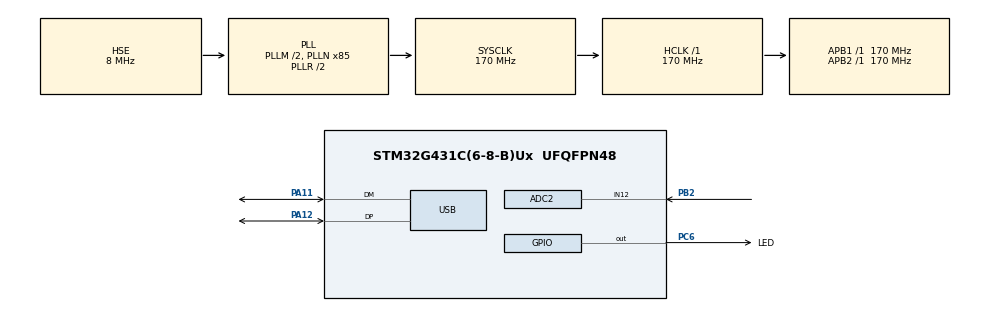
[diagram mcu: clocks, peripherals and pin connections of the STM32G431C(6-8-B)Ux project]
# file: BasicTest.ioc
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ADC2.Channel-0\#ChannelRegularConversion=ADC_CHANNEL_12
ADC2.ContinuousConvMode=ENABLE
ADC2.DMAContinuousRequests=ENABLE
ADC2.NbrOfConversionFlag=1
ADC2.OffsetNumber-0\#ChannelRegularConversion=ADC_OFFSET_NONE
ADC2.Rank-0\#ChannelRegularConversion=1
ADC2.SamplingTime-0\#ChannelRegularConversion=ADC_SAMPLETIME_640CYCLES_5
Dma.ADC2.0.Direction=DMA_PERIPH_TO_MEMORY
Dma.ADC2.0.EventEnable=DISABLE
Dma.ADC2.0.Instance=DMA1_Channel1
Dma.ADC2.0.MemDataAlignment=DMA_MDATAALIGN_HALFWORD
Dma.ADC2.0.MemInc=DMA_MINC_ENABLE
Dma.ADC2.0.Mode=DMA_CIRCULAR
Dma.ADC2.0.PeriphDataAlignment=DMA_PDATAALIGN_HALFWORD
Dma.ADC2.0.PeriphInc=DMA_PINC_DISABLE
Dma.ADC2.0.Polarity=HAL_DMAMUX_REQ_GEN_RISING
Dma.ADC2.0.Priority=DMA_PRIORITY_LOW
Dma.ADC2.0.RequestNumber=1
Dma.ADC2.0.SignalID=NONE
Dma.ADC2.0.SyncEnable=DISABLE
Dma.ADC2.0.SyncPolarity=HAL_DMAMUX_SYNC_NO_EVENT
Dma.ADC2.0.SyncRequestNumber=1
Dma.ADC2.0.SyncSignalID=NONE
Dma.Request0=ADC2
FREERTOS.Tasks01=defaultTask,0,128,StartDefaultTask,Default,NULL,Dynamic,NULL,NULL
Mcu.Family=STM32G4
Mcu.Name=STM32G431C(6-8-B)Ux
Mcu.Package=UFQFPN48
NVIC.DMA1_Channel1_IRQn=true\:5\:0\:false\:false\:true\:true\:false\:true\:true
NVIC.PriorityGroup=NVIC_PRIORITYGROUP_4
NVIC.TIM1_TRG_COM_TIM17_IRQn=true\:15\:0\:false\:false\:true\:false\:false\:true\:true
NVIC.TimeBase=TIM1_TRG_COM_TIM17_IRQn
NVIC.TimeBaseIP=TIM17
NVIC.USB_LP_IRQn=true\:5\:0\:false\:false\:true\:true\:false\:true\:true
PA11.Mode=Device
PA11.Signal=USB_DM
PA12.Mode=Device
PA12.Signal=USB_DP
PA13.Mode=Serial_Wire
PA13.Signal=SYS_JTMS-SWDIO
PA14.Mode=Serial_Wire
PA14.Signal=SYS_JTCK-SWCLK
PB2.Mode=IN12-Single-Ended
PB2.Signal=ADC2_IN12
PC6.GPIO_Label=LED
PC6.GPIO_PuPd=GPIO_PULLDOWN
PC6.GPIO_Speed=GPIO_SPEED_FREQ_LOW
PC6.PinState=GPIO_PIN_RESET
PC6.Signal=GPIO_Output
PF0-OSC_IN.Mode=HSE-External-Oscillator
PF0-OSC_IN.Signal=RCC_OSC_IN
PF1-OSC_OUT.Mode=HSE-External-Oscillator
PF1-OSC_OUT.Signal=RCC_OSC_OUT
ProjectManager.HeapSize=0x100
ProjectManager.StackSize=0xA00
ProjectManager.TargetToolchain=MDK-ARM V5.32
RCC.ADC12Freq_Value=170000000
RCC.AHBFreq_Value=170000000
RCC.APB1Freq_Value=170000000
RCC.APB1TimFreq_Value=170000000
RCC.APB2Freq_Value=170000000
RCC.APB2TimFreq_Value=170000000
RCC.CK48CLockSelection=RCC_USBCLKSOURCE_HSI48
RCC.CortexFreq_Value=170000000
RCC.EXTERNAL_CLOCK_VALUE=12288000
RCC.HCLKFreq_Value=170000000
RCC.HSE_VALUE=8000000
RCC.HSI48_VALUE=48000000
RCC.HSI_VALUE=16000000
RCC.LSE_VALUE=32768
RCC.PLLM=RCC_PLLM_DIV2
RCC.PLLN=85
RCC.PLLSourceVirtual=RCC_PLLSOURCE_HSE
RCC.SYSCLKFreq_VALUE=170000000
RCC.SYSCLKSource=RCC_SYSCLKSOURCE_PLLCLK
RCC.USBFreq_Value=48000000
RCC.VCOOutputFreq_Value=340000000
TIM7.Prescaler=169
USB_DEVICE.CLASS_NAME_FS=CDC
USB_DEVICE.VirtualMode=Cdc
USB_DEVICE.VirtualModeFS=Cdc_FS
VP_FREERTOS_VS_CMSIS_V1.Mode=CMSIS_V1
VP_SYS_VS_DBSignals.Mode=DisableDeadBatterySignals
VP_SYS_VS_tim17.Mode=TIM17
VP_TIM7_VS_ClockSourceINT.Mode=Enable_Timer
VP_USB_DEVICE_VS_USB_DEVICE_CDC_FS.Mode=CDC_FS
board=custom

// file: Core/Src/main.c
/* USER CODE BEGIN Header */
/**
  ******************************************************************************
  * @file           : main.c
  * @brief          : Main program body
  ******************************************************************************
  * @attention
  *
  * Copyright (c) 2025 STMicroelectronics.
  * All rights reserved.
  *
  * This software is licensed under terms that can be found in the LICENSE file
  * in the root directory of this software component.
  * If no LICENSE file comes with this software, it is provided AS-IS.
  *
  ******************************************************************************
  */
/* USER CODE END Header */
#include "main.h"
#include "cmsis_os.h"
#include "adc.h"
#include "dma.h"
#include "tim.h"
#include "usb_device.h"
#include "gpio.h"

void SystemClock_Config(void);
void MX_FREERTOS_Init(void);

int main(void)
{

  /* MCU Configuration--------------------------------------------------------*/

  /* Reset of all peripherals, Initializes the Flash interface and the Systick. */
  HAL_Init();

  /* Configure the system clock */
  SystemClock_Config();

  /* Initialize all configured peripherals */
  MX_GPIO_Init();
  MX_DMA_Init();
  MX_USB_Device_Init();
  MX_ADC2_Init();
  MX_TIM7_Init();
  /* USER CODE BEGIN 2 */
  LL_TIM_SetCounter(TIM7, 0);
//	LL_TIM_EnableIT_UPDATE(TIM7);//start TIM7 IRQ
	LL_TIM_EnableCounter(TIM7);//Enable TIM7
  /* USER CODE END 2 */

  /* Call init function for freertos objects (in freertos.c) */
  MX_FREERTOS_Init();

  /* Start scheduler */
  osKernelStart();

  /* We should never get here as control is now taken by the scheduler */
  /* Infinite loop */
  while (1)
  {

  }
}

void SystemClock_Config(void)
{
  RCC_OscInitTypeDef RCC_OscInitStruct = {0};
  RCC_ClkInitTypeDef RCC_ClkInitStruct = {0};

  /** Configure the main internal regulator output voltage
  */
  HAL_PWREx_ControlVoltageScaling(PWR_REGULATOR_VOLTAGE_SCALE1_BOOST);

  /** Initializes the RCC Oscillators according to the specified parameters
  * in the RCC_OscInitTypeDef structure.
  */
  RCC_OscInitStruct.OscillatorType = RCC_OSCILLATORTYPE_HSI48|RCC_OSCILLATORTYPE_HSE;
  RCC_OscInitStruct.HSEState = RCC_HSE_ON;
  RCC_OscInitStruct.HSI48State = RCC_HSI48_ON;
  RCC_OscInitStruct.PLL.PLLState = RCC_PLL_ON;
  RCC_OscInitStruct.PLL.PLLSource = RCC_PLLSOURCE_HSE;
  RCC_OscInitStruct.PLL.PLLM = RCC_PLLM_DIV2;
  RCC_OscInitStruct.PLL.PLLN = 85;
  RCC_OscInitStruct.PLL.PLLP = RCC_PLLP_DIV2;
  RCC_OscInitStruct.PLL.PLLQ = RCC_PLLQ_DIV2;
  RCC_OscInitStruct.PLL.PLLR = RCC_PLLR_DIV2;
  if (HAL_RCC_OscConfig(&RCC_OscInitStruct) != HAL_OK)
  {
    Error_Handler();
  }

  /** Initializes the CPU, AHB and APB buses clocks
  */
  RCC_ClkInitStruct.ClockType = RCC_CLOCKTYPE_HCLK|RCC_CLOCKTYPE_SYSCLK
                              |RCC_CLOCKTYPE_PCLK1|RCC_CLOCKTYPE_PCLK2;
  RCC_ClkInitStruct.SYSCLKSource = RCC_SYSCLKSOURCE_PLLCLK;
  RCC_ClkInitStruct.AHBCLKDivider = RCC_SYSCLK_DIV1;
  RCC_ClkInitStruct.APB1CLKDivider = RCC_HCLK_DIV1;
  RCC_ClkInitStruct.APB2CLKDivider = RCC_HCLK_DIV1;

  if (HAL_RCC_ClockConfig(&RCC_ClkInitStruct, FLASH_LATENCY_4) != HAL_OK)
  {
    Error_Handler();
  }
}

void HAL_TIM_PeriodElapsedCallback(TIM_HandleTypeDef *htim)
{
  if (htim->Instance == TIM17) {
    HAL_IncTick();
  }
}

void Error_Handler(void)
{
  __disable_irq();
  while (1)
  {
  }
}

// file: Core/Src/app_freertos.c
/* USER CODE BEGIN Header */
/**
  ******************************************************************************
  * File Name          : app_freertos.c
  * Description        : Code for freertos applications
  ******************************************************************************
  * @attention
  *
  * Copyright (c) 2025 STMicroelectronics.
  * All rights reserved.
  *
  * This software is licensed under terms that can be found in the LICENSE file
  * in the root directory of this software component.
  * If no LICENSE file comes with this software, it is provided AS-IS.
  *
  ******************************************************************************
  */
/* USER CODE END Header */

#include "FreeRTOS.h"
#include "task.h"
#include "main.h"
#include "cmsis_os.h"

osThreadId defaultTaskHandle;

void StartDefaultTask(void const * argument);

void MX_FREERTOS_Init(void); /* (MISRA C 2004 rule 8.1) */

void MX_FREERTOS_Init(void) {

  /* Create the thread(s) */
  /* definition and creation of defaultTask */
  osThreadDef(defaultTask, StartDefaultTask, osPriorityNormal, 0, 128);
  defaultTaskHandle = osThreadCreate(osThread(defaultTask), NULL);

}

/* USER CODE BEGIN Header_StartDefaultTask */
/**
  * @brief  Function implementing the defaultTask thread.
  * @param  argument: Not used
  * @retval None
  */
uint16_t adc_value[10];
/* USER CODE END Header_StartDefaultTask */
void StartDefaultTask(void const * argument)
{
  /* USER CODE BEGIN StartDefaultTask */
	char usb_buff[128]={0};
	HAL_ADC_Start_DMA(&hadc2, (uint32_t *)adc_value, 10);
  /* Infinite loop */
	for(;;)
	{
		HAL_GPIO_TogglePin(LED_GPIO_Port,LED_Pin);
		sprintf(usb_buff,"PB2 adc_value:%d\r\n",adc_value[0]);
		CDC_Transmit_FS((uint8_t *)usb_buff,strlen(usb_buff));
//		for(uint16_t i =0; i<500;i++)
//		user_delaynus_tim(1000);
		osDelay(500);
	}
  /* USER CODE END StartDefaultTask */
}

/* USER CODE BEGIN Application */
void user_delaynus_tim(uint16_t nus)
{

	LL_TIM_SetCounter(TIM7, 0);
	while (LL_TIM_GetCounter(TIM7) < nus)
	{
		;// Optionally, add a timeout condition here to avoid an infinite loop
	}
}
/* USER CODE END Application */
